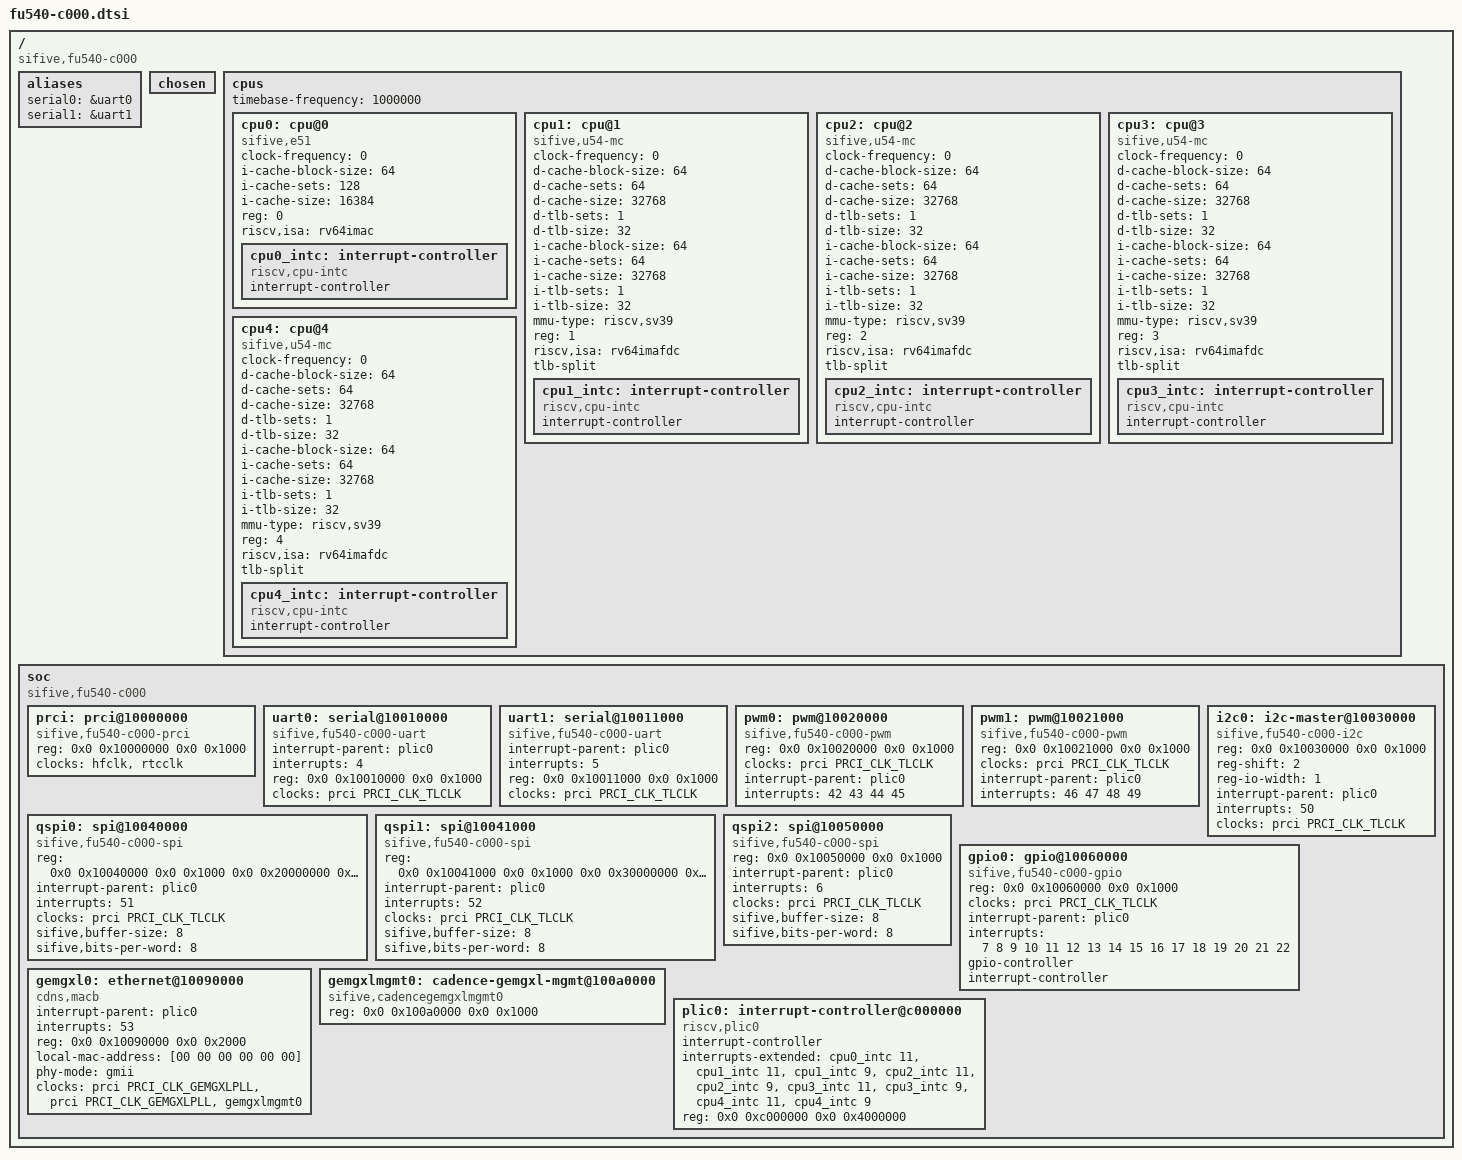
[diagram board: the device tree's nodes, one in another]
// SPDX-License-Identifier: Apache-2.0
// SPDX-License-Identifier: GPL-2.0-or-later
/* Copyright (c) 2018 SiFive, Inc */
/* See the file LICENSE for further information */

/dts-v1/;

#include <dt-bindings/clock/sifive-fu540-prci.h>

/ {
	#address-cells = <2>;
	#size-cells = <2>;
	compatible = "sifive,fu540-c000", "sifive,fu540";

	aliases {
		serial0 = &uart0;
		serial1 = &uart1;
	};

	chosen {
	};

	cpus {
		#address-cells = <1>;
		#size-cells = <0>;
		timebase-frequency = <1000000>;
		cpu0: cpu@0 {
			clock-frequency = <0>;
			compatible = "sifive,e51", "sifive,rocket0";
			device_type = "cpu";
			i-cache-block-size = <64>;
			i-cache-sets = <128>;
			i-cache-size = <16384>;
			reg = <0>;
			riscv,isa = "rv64imac";
			status = "okay";
			cpu0_intc: interrupt-controller {
				#interrupt-cells = <1>;
				compatible = "riscv,cpu-intc";
				interrupt-controller;
			};
		};
		cpu1: cpu@1 {
			clock-frequency = <0>;
			compatible = "sifive,u54-mc", "sifive,rocket0";
			d-cache-block-size = <64>;
			d-cache-sets = <64>;
			d-cache-size = <32768>;
			d-tlb-sets = <1>;
			d-tlb-size = <32>;
			device_type = "cpu";
			i-cache-block-size = <64>;
			i-cache-sets = <64>;
			i-cache-size = <32768>;
			i-tlb-sets = <1>;
			i-tlb-size = <32>;
			mmu-type = "riscv,sv39";
			reg = <1>;
			riscv,isa = "rv64imafdc";
			status = "okay";
			tlb-split;
			cpu1_intc: interrupt-controller {
				#interrupt-cells = <1>;
				compatible = "riscv,cpu-intc";
				interrupt-controller;
			};
		};
		cpu2: cpu@2 {
			clock-frequency = <0>;
			compatible = "sifive,u54-mc", "sifive,rocket0";
			d-cache-block-size = <64>;
			d-cache-sets = <64>;
			d-cache-size = <32768>;
			d-tlb-sets = <1>;
			d-tlb-size = <32>;
			device_type = "cpu";
			i-cache-block-size = <64>;
			i-cache-sets = <64>;
			i-cache-size = <32768>;
			i-tlb-sets = <1>;
			i-tlb-size = <32>;
			mmu-type = "riscv,sv39";
			reg = <2>;
			riscv,isa = "rv64imafdc";
			status = "okay";
			tlb-split;
			cpu2_intc: interrupt-controller {
				#interrupt-cells = <1>;
				compatible = "riscv,cpu-intc";
				interrupt-controller;
			};
		};
		cpu3: cpu@3 {
			clock-frequency = <0>;
			compatible = "sifive,u54-mc", "sifive,rocket0";
			d-cache-block-size = <64>;
			d-cache-sets = <64>;
			d-cache-size = <32768>;
			d-tlb-sets = <1>;
			d-tlb-size = <32>;
			device_type = "cpu";
			i-cache-block-size = <64>;
			i-cache-sets = <64>;
			i-cache-size = <32768>;
			i-tlb-sets = <1>;
			i-tlb-size = <32>;
			mmu-type = "riscv,sv39";
			reg = <3>;
			riscv,isa = "rv64imafdc";
			status = "okay";
			tlb-split;
			cpu3_intc: interrupt-controller {
				#interrupt-cells = <1>;
				compatible = "riscv,cpu-intc";
				interrupt-controller;
			};
		};
		cpu4: cpu@4 {
			clock-frequency = <0>;
			compatible = "sifive,u54-mc", "sifive,rocket0";
			d-cache-block-size = <64>;
			d-cache-sets = <64>;
			d-cache-size = <32768>;
			d-tlb-sets = <1>;
			d-tlb-size = <32>;
			device_type = "cpu";
			i-cache-block-size = <64>;
			i-cache-sets = <64>;
			i-cache-size = <32768>;
			i-tlb-sets = <1>;
			i-tlb-size = <32>;
			mmu-type = "riscv,sv39";
			reg = <4>;
			riscv,isa = "rv64imafdc";
			status = "okay";
			tlb-split;
			cpu4_intc: interrupt-controller {
				#interrupt-cells = <1>;
				compatible = "riscv,cpu-intc";
				interrupt-controller;
			};
		};
	};
	soc {
		#address-cells = <2>;
		#size-cells = <2>;
		compatible = "sifive,fu540-c000", "sifive,fu540", "simple-bus";
		ranges;
		prci: prci@10000000 {
			compatible = "sifive,fu540-c000-prci";
			reg = <0x0 0x10000000 0x0 0x1000>;
			clocks = <&hfclk>, <&rtcclk>;
			#clock-cells = <1>;
		};
		uart0: serial@10010000 {
			compatible = "sifive,fu540-c000-uart", "sifive,uart0";
			interrupt-parent = <&plic0>;
			interrupts = <4>;
			reg = <0x0 0x10010000 0x0 0x1000>;
			clocks = <&prci PRCI_CLK_TLCLK>;
		};
		uart1: serial@10011000 {
			compatible = "sifive,fu540-c000-uart", "sifive,uart0";
			interrupt-parent = <&plic0>;
			interrupts = <5>;
			reg = <0x0 0x10011000 0x0 0x1000>;
			clocks = <&prci PRCI_CLK_TLCLK>;
		};
		pwm0: pwm@10020000 {
			compatible = "sifive,fu540-c000-pwm", "sifive,pwm0";
			reg = <0x0 0x10020000 0x0 0x1000>;
			clocks = <&prci PRCI_CLK_TLCLK>;
			interrupt-parent = <&plic0>;
			interrupts = <42 43 44 45>;
			#pwm-cells = <2>;
		};
		pwm1: pwm@10021000 {
			compatible = "sifive,fu540-c000-pwm", "sifive,pwm0";
			reg = <0x0 0x10021000 0x0 0x1000>;
			clocks = <&prci PRCI_CLK_TLCLK>;
			interrupt-parent = <&plic0>;
			interrupts = <46 47 48 49>;
			#pwm-cells = <2>;
		};
		i2c0: i2c-master@10030000 {
			compatible = "sifive,fu540-c000-i2c", "sifive,i2c0", "opencores,i2c-ocores";
			reg = <0x0 0x10030000 0x0 0x1000>;
			reg-shift = <2>;
			reg-io-width = <1>;
			interrupt-parent = <&plic0>;
			interrupts = <50>;
			clocks = <&prci PRCI_CLK_TLCLK>;
			#address-cells = <1>;
			#size-cells = <0>;
		};
		qspi0: spi@10040000 {
			compatible = "sifive,fu540-c000-spi", "sifive,spi0";
			reg = <0x0 0x10040000 0x0 0x1000 0x0 0x20000000 0x0 0x10000000>;
			interrupt-parent = <&plic0>;
			interrupts = <51>;
			clocks = <&prci PRCI_CLK_TLCLK>;
			#address-cells = <1>;
			#size-cells = <0>;
			sifive,buffer-size = <8>;
			sifive,bits-per-word = <8>;
		};
		qspi1: spi@10041000 {
			compatible = "sifive,fu540-c000-spi", "sifive,spi0";
			reg = <0x0 0x10041000 0x0 0x1000 0x0 0x30000000 0x0 0x10000000>;
			interrupt-parent = <&plic0>;
			interrupts = <52>;
			clocks = <&prci PRCI_CLK_TLCLK>;
			#address-cells = <1>;
			#size-cells = <0>;
			sifive,buffer-size = <8>;
			sifive,bits-per-word = <8>;
		};
		qspi2: spi@10050000 {
			compatible = "sifive,fu540-c000-spi", "sifive,spi0";
			reg = <0x0 0x10050000 0x0 0x1000>;
			interrupt-parent = <&plic0>;
			interrupts = <6>;
			clocks = <&prci PRCI_CLK_TLCLK>;
			#address-cells = <1>;
			#size-cells = <0>;
			sifive,buffer-size = <8>;
			sifive,bits-per-word = <8>;
		};
		gpio0: gpio@10060000 {
			compatible = "sifive,fu540-c000-gpio", "sifive,gpio0";
			reg = <0x0 0x10060000 0x0 0x1000>;
			clocks = <&prci PRCI_CLK_TLCLK>;
			interrupt-parent = <&plic0>;
			interrupts = <7 8 9 10 11 12 13 14 15 16 17 18 19 20 21 22>;
			gpio-controller;
			interrupt-controller;
			#gpio-cells = <2>;
			#interrupt-cells = <2>;
		};
		gemgxl0: ethernet@10090000 {
			compatible = "cdns,macb";
			interrupt-parent = <&plic0>;
			interrupts = <53>;
			reg = <0x0 0x10090000 0x0 0x2000>;
			reg-names = "control";

			local-mac-address = [00 00 00 00 00 00];
			phy-mode = "gmii";
			clock-names = "pclk", "hclk", "tx_clk";
			clocks = <&prci PRCI_CLK_GEMGXLPLL>, <&prci PRCI_CLK_GEMGXLPLL>, <&gemgxlmgmt0>;

			#address-cells = <1>;
			#size-cells = <0>;
		};
		gemgxlmgmt0: cadence-gemgxl-mgmt@100a0000 {
			compatible = "sifive,cadencegemgxlmgmt0";
			#clock-cells = <0>;
			reg = <0x0 0x100a0000 0x0 0x1000>;
		};
		plic0: interrupt-controller@c000000 {
			#interrupt-cells = <1>;
			compatible = "riscv,plic0";
			interrupt-controller;
			interrupts-extended = <
				&cpu0_intc 11
				&cpu1_intc 11 &cpu1_intc 9
				&cpu2_intc 11 &cpu2_intc 9
				&cpu3_intc 11 &cpu3_intc 9
				&cpu4_intc 11 &cpu4_intc 9>;
			reg = <0x0 0xc000000 0x0 0x4000000>;
		};
	};
};
